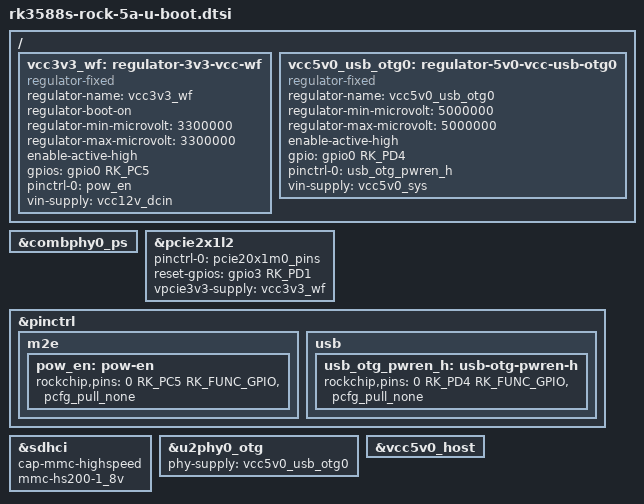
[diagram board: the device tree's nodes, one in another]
// SPDX-License-Identifier: (GPL-2.0+ OR MIT)
/*
 * Copyright (c) 2023 Collabora Ltd.
 */

#include "rk3588s-u-boot.dtsi"

/ {
	vcc3v3_wf: regulator-3v3-vcc-wf {
		compatible = "regulator-fixed";
		regulator-name = "vcc3v3_wf";
		regulator-boot-on;
		regulator-min-microvolt = <3300000>;
		regulator-max-microvolt = <3300000>;
		enable-active-high;
		gpios = <&gpio0 RK_PC5 GPIO_ACTIVE_HIGH>;
		pinctrl-names = "default";
		pinctrl-0 = <&pow_en>;
		vin-supply = <&vcc12v_dcin>;
	};

	vcc5v0_usb_otg0: regulator-5v0-vcc-usb-otg0 {
		compatible = "regulator-fixed";
		regulator-name = "vcc5v0_usb_otg0";
		regulator-min-microvolt = <5000000>;
		regulator-max-microvolt = <5000000>;
		enable-active-high;
		gpio = <&gpio0 RK_PD4 GPIO_ACTIVE_HIGH>;
		pinctrl-names = "default";
		pinctrl-0 = <&usb_otg_pwren_h>;
		vin-supply = <&vcc5v0_sys>;
	};
};

&combphy0_ps {
	status = "okay";
};

&pcie2x1l2 {
	pinctrl-names = "default";
	pinctrl-0 = <&pcie20x1m0_pins>;
	reset-gpios = <&gpio3 RK_PD1 GPIO_ACTIVE_HIGH>;
	vpcie3v3-supply = <&vcc3v3_wf>;
	status = "okay";
};

&pinctrl {
	m2e {
		pow_en: pow-en {
			rockchip,pins = <0 RK_PC5 RK_FUNC_GPIO &pcfg_pull_none>;
		};
	};

	usb {
		usb_otg_pwren_h: usb-otg-pwren-h {
			rockchip,pins = <0 RK_PD4 RK_FUNC_GPIO &pcfg_pull_none>;
		};
	};
};

&sdhci {
	cap-mmc-highspeed;
	mmc-hs200-1_8v;
};

&u2phy0_otg {
	phy-supply = <&vcc5v0_usb_otg0>;
};

&vcc5v0_host {
	/delete-property/ regulator-always-on;
	/delete-property/ regulator-boot-on;
};
